# STM32H7S register map
File version: 1.4
CPU: CM7 r0p1, little endian, MPU, FPU, 4 interrupt priority bits
Registers are 32-bit, read-write, reset 0x0 unless marked. A register's access mark holds for its fields unless they carry their own. Offsets are from the block's base; [hi:lo] are bit positions; {n}, {i} and the like mark numbered series; 'fields as' and 'values as' point back to an identical list.

## PWR — Power control
Base 0x58024800
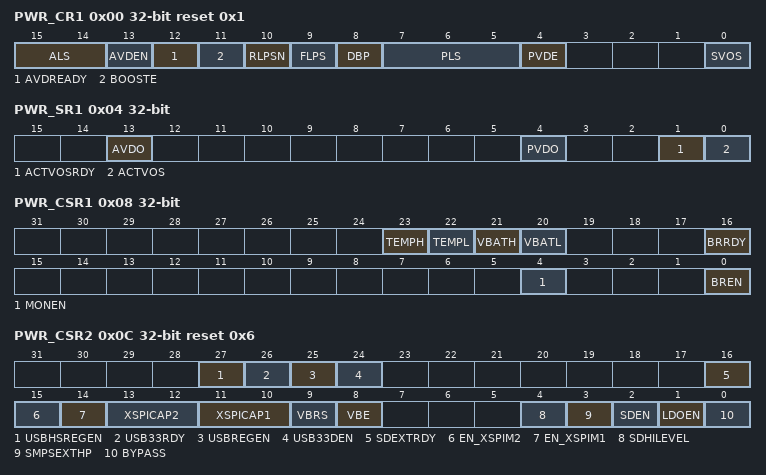
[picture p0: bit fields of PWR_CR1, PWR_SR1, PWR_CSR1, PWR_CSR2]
0x00 PWR_CR1 reset 0x1 — PWR control register 1
  [15:14] ALS — Analog voltage detector level selection These bits select the voltage threshold detected by the AVD. Note: Refer to Section Electrical characteristics of the product datasheet for more details.
    {v}=AVD level {v+1} (v=0..3)
  [13] AVDEN — Peripheral voltage monitor on VDDA enable
    0=Peripheral voltage monitor on VDDA disabled; 1=Peripheral voltage monitor on VDDA enabled
  [12] AVDREADY — analog voltage ready This bit is only used when the analog switch boost needs to be enabled (see BOOSTE bit). It must be set by software when the expected VDDA analog supply level is available. The correct analog supply level is indicated by the AVDO bit (PWR_CSR1 register) after setting the AVDEN bit and selecting the supply level to be monitored (ALS bits).
    0=peripheral analog voltage VDDA not ready (default); 1=peripheral analog voltage VDDA ready
  [11] BOOSTE — analog switch VBoost control This bit enables the booster to guarantee the analog switch AC performance when the VDD supply voltage is below 2.7 V (reduction of the total harmonic distortion to have the same switch performance over the full supply voltage range) The VDD supply voltage can be monitored through the PVD and the PLS bits.
    0=booster disabled (default); 1=booster enabled if analog voltage ready (AVD_READY = 1)
  [10] RLPSN — RAM low power mode disable in STOP. When set the RAMs will not enter to low power mode when the system enters to STOP.
    0=RAM enters to low power mode when system enters to STOP; 1=RAM remains in normal mode when system enters to STOP
  [9] FLPS — Flash low-power mode in Stop mode This bit allows to obtain the best trade-off between low-power consumption and restart time when exiting from Stop mode. When it is set, the Flash memory enters low-power mode when device is in Stop mode. consumption).
    0=Flash memory remains in normal mode when device enters Stop (quick restart time); 1=Flash memory enters low-power mode when device enters Stop mode (low-power
  [8] DBP — Disable backup domain write protection In reset state, the RCC_BDCR register, the RTC registers (including the backup registers), BREN and MOEN bits in the PWR_CSR1 register, are protected against parasitic write access. This bit must be set to enable write access to these registers.
    0=Access to RTC, RTC backup registers and backup SRAM disabled; 1=Access to RTC, RTC backup registers and backup SRAM enabled
  [7:5] PLS — Programmable voltage detector level selection These bits select the voltage threshold detected by the PVD. Note: Refer to Section Electrical characteristics of the product datasheet for more details.
    {v}=PVD level {v+1} (v=0..6); 7=External voltage level on PVD_IN pin, compared to internal VREFINT level
  [4] PVDE — Programmable voltage detector enable
    0=Programmable voltage detector disabled; 1=Programmable voltage detector enabled
  [0] SVOS — System Stop mode voltage scaling selection.
    0=SVOS Low; 1=SVOS High (default)
0x04 PWR_SR1 ro — PWR control status register 1
  [13] AVDO — Analog voltage detector output on VDDA This bit is set and cleared by hardware. It is valid only if AVD on VDDA is enabled by the AVDEN bit. Note: Since the AVD is disabled in Standby mode, this bit is equal to 0 after Standby or reset until the AVDEN bit is set
    0=VDDA is equal or higher than the AVD threshold selected with the ALS[1:0] bits; 1=VDDA is lower than the AVD threshold selected with the ALS[1:0] bits
  [4] PVDO — Programmable voltage detect output This bit is set and cleared by hardware. It is valid only if the PVD has been enabled by the PVDE bit. PLS[2:0] bits. bits. Note: Since the PVD is disabled in Standby mode, this bit is equal to 0 after Standby or reset until the PVDE bit is set.
    0=VDD or PVD_IN voltage is equal or higher than the PVD threshold selected through the; 1=VDD or PVD_IN voltage is lower than the PVD threshold selected through the PLS[2:0]
  [1] ACTVOSRDY — Voltage levels ready bit for currently used ACTVOS and SDHILEVEL This bit is set to 1 by hardware when the voltage regulator and the SMPS step-down converter are both disabled and Bypass mode is selected in PWR control register 2 (PWR_CSR2).
    0=Voltage level invalid, above or below current ACTVOS and SDHILEVEL selected levels; 1=Voltage level valid, at current ACTVOS and SDHILEVEL selected levels
  [0] ACTVOS — VOS currently applied for V<sub>CORE</sub> voltage scaling selection. These bit reflect the last VOS value applied to the PMU.
0x08 PWR_CSR1 access per field — PWR control status register 1
  [23] TEMPH ro — Temperature level monitoring versus high threshold
    0=Temperature below high threshold level; 1=Temperature equal or above high threshold level
  [22] TEMPL ro — Temperature level monitoring versus low threshold
    0=Temperature above low threshold level; 1=Temperature equal or below low threshold level
  [21] VBATH ro — V<sub>BAT</sub> level monitoring versus high threshold
    0=V<sub>BAT</sub> level below high threshold level; 1=V<sub>BAT</sub> level equal or above high threshold level
  [20] VBATL ro — V<sub>BAT</sub> level monitoring versus low threshold
    0=V<sub>BAT</sub> level above low threshold level; 1=V<sub>BAT</sub> level equal or below low threshold level
  [16] BRRDY ro — Backup regulator ready This bit is set by hardware to indicate that the backup regulator is ready.
    0=Backup regulator not ready; 1=Backup regulator ready
  [4] MONEN rw — V<sub>BAT</sub> and temperature monitoring enable When set, the V<sub>BAT</sub> supply and temperature monitoring is enabled. Note: V<sub>BAT</sub> and temperature monitoring are only available when the backup regulator is enabled (BREN bit set to 1).
    0=V<sub>BAT</sub> and temperature monitoring disabled; 1=V<sub>BAT</sub> and temperature monitoring enabled
  [0] BREN rw — Backup regulator enable When set, the backup regulator (used to maintain the backup RAM content in Standby and V<sub>BAT</sub> modes) is enabled. If BREN is reset, the backup regulator is switched off. The backup RAM can still be used in Run and Stop modes. However, its content will be lost in Standby and V<sub>BAT</sub> modes. If BREN is set, the application must wait till the backup regulator ready flag (BRRDY) is set to indicate that the data written into the SRAM will be maintained in Standby and V<sub>BAT</sub> modes.
    0=Backup regulator disabled; 1=Backup regulator enabled
0x0C PWR_CSR2 access per field reset 0x6 — PWR control register 2
  [27] USBHSREGEN rw — USB HS regulator enable.
    0=USB HS PHY regulator disabled (default); 1=USB HS PHY regulator enabled
  [26] USB33RDY ro — USB supply ready.
    0=USB33 supply not ready; 1=USB33 supply ready
  [25] USBREGEN rw — USB regulator enable.
    0=USB regulator disabled; 1=USB regulator enabled
  [24] USB33DEN rw — VDD33_USB voltage level detector enable
    0=VDD33_USB voltage level detector disabled; 1=VDD33_USB voltage level detector enabled
  [16] SDEXTRDY ro — SMPS step-down converter external supply ready This bit is set by hardware to indicate that the external supply from the SMPS step-down converter is ready.
    0=External supply not ready; 1=External supply ready
  [15] EN_XSPIM2 rw — EN_XSPIM2: this bit allows the SW to enable the XSPI interface, when available. The XSPIM_P2 supply must be stable prior to setting this bit. It should also be set when FMC is used.
  [14] EN_XSPIM1 rw — EN_XSPIM1: this bit allow the SW to enable the XSPI interface. The XSPIM_P1 supply must be stable prior to setting this bit.
  [13:12] XSPICAP2 rw — XSPI port 2 capacitor control bits see the product datasheet for more details
    0=XSPI Capacitor OFF (default) note: to confirm with analog design; 1=XSPI Capacitor set to 1/3; 2=XSPI Capacitor set to 2/3; 3=XSPI Capacitor set to full capacitance
  [11:10] XSPICAP1 rw — XSPI port 1 capacitor control bits see the product datasheet for more details
    values as XSPICAP2
  [9] VBRS rw — VBAT charging resistor selection
    0=Charge VBAT through a 5 k resistor; 1=Charge VBAT through a 1.5 k resistor
  [8] VBE rw — VBAT charging enable
    0=VBAT battery charging disabled; 1=VBAT battery charging enabled
  [4] SDHILEVEL rw-once — SMPS step-down converter voltage output for LDO or external supply This bit is used when both the LDO and SMPS step-down converter are enabled with SDEN and LDOEN enabled or when SMPSEXTHP is enabled. In this case SDHILEVEL has to be set to 1 to confirm the regulator settings
    0=Reset value; 1=1.8V
  [3] SMPSEXTHP rw-once — SMPS external power delivery selection Note: Illegal combinations of SDHILEVEL, SMPSEXTHP, SDEN, LDOEN and BYPASS are described in Table 41.
    0=SMPS normal operating mode, no power delivery to external circuits; 1=SMPS external operating mode, power delivery to external circuits
  [2] SDEN rw-once — SMPS step-down converter enable Note: Illegal combinations of SDHILEVEL, SMPSEXTHP, SDEN, LDOEN and BYPASS are described in Table 41.
    0=SMPS step-down converter disabled
  [1] LDOEN rw-once — Low drop-out regulator enable Note: Illegal combinations of SDHILEVEL, SMPSEXTHP, SDEN, LDOEN and BYPASS are described in Table 41.
    0=Low drop-out regulator disabled; 1=Low drop-out regulator enabled (default)
  [0] BYPASS rw-once — Power management unit bypass Note: Illegal combinations of SDHILEVEL, SMPSEXTHP, SDEN, LDOEN and BYPASS are described in Table 41.
    0=Power management unit normal operation; 1=Power management unit bypassed, voltage monitoring still active
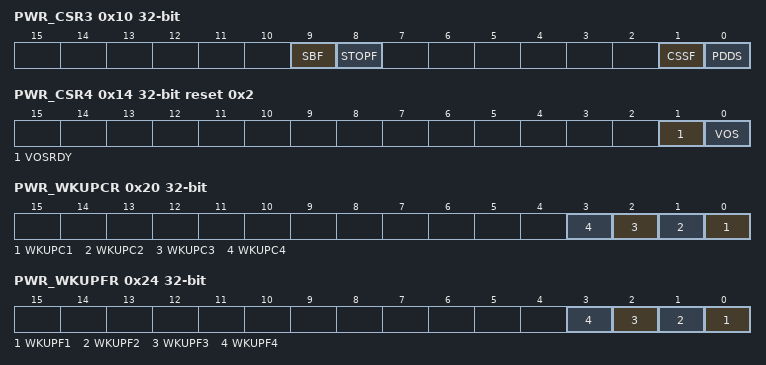
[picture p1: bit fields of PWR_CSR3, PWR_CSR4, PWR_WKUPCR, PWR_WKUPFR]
0x10 PWR_CSR3 access per field — PWR CPU control register 3
  [9] SBF ro — System Standby flag This bit is set by hardware and cleared only by a POR (Power-on Reset) or by setting the CPU CSSF bit
    0=System has not been in Standby mode; 1=System has been in Standby mode
  [8] STOPF ro — STOP flag This bit is set by hardware and cleared only by any reset or by setting the CPU CSSF bit.
    0=System has not been in Stop mode; 1=System has been in Stop mode
  [1] CSSF rw — Clear Standby and Stop flags (always read as 0) This bit is cleared to 0 by hardware.
    0=No effect; 1=flags (STOPF, SBF) are cleared
  [0] PDDS rw — Power Down Deepsleep. This bit allows CPU to define the Deepsleep mode
    0=Stop mode when device enters Deepsleep; 1=Standby mode when device enters Deepsleep
0x14 PWR_CSR4 access per field reset 0x2 — PWR control status register 4
  [1] VOSRDY ro — VOS Ready bit
    0=Not ready, voltage level below VOS selected level; 1=Ready, voltage level at or above VOS selected level
  [0] VOS rw — Voltage scaling selection according to performance These bits control the V<sub>CORE</sub> voltage level and allow to obtains the best trade-off between power consumption and performance: When increasing the performance, the voltage scaling must be changed before increasing the system frequency. When decreasing performance, the system frequency must first be decreased before changing the voltage scaling. Note: Refer to Section Electrical characteristics of the product datasheet for more details.
    0=VOS Low level (default); 1=VOS High level
0x20 PWR_WKUPCR — PWR wakeup clear register
  [n-1] WKUPC{n} (n=1..4) — Clear Wakeup pin flag for WKUP{n} These bits are always read as 0.
    0=No effect; 1=Writing 1 clears the WKUPF{n} Wakeup pin flag (bit is cleared to 0 by hardware)
0x24 PWR_WKUPFR ro — PWR wakeup flag register
  [n-1] WKUPF{n} (n=1..4) — Wakeup pin WKUP{n} flag. This bit is set by hardware and cleared only by a Reset pin or by setting the WKUPC{n} bit in the PWR wakeup clear register (PWR_WKUPCR).
    0=No wakeup event occurred; 1=A wakeup event was received from WKUP{n} pin
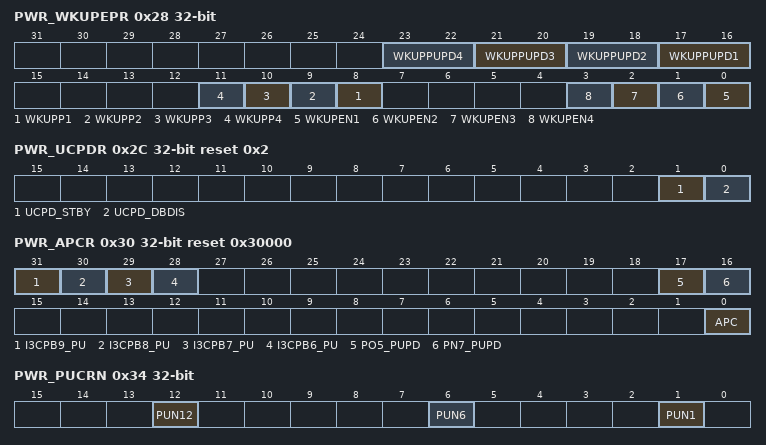
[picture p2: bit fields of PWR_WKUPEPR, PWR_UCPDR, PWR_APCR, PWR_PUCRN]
0x28 PWR_WKUPEPR — PWR wakeup enable and polarity register
  [2n+15:2n+14] WKUPPUPD{n} (n=1..4) — Wakeup pin pull configuration for WKUPn, These bits define the I/O pad pull configuration used when WKUPENn = 1. The associated GPIO port pull configuration must be set to the same value or to 00. The Wakeup pin pull configuration is kept in Standby mode.
    0=No pull-up; 1=Pull-up; 2=Pull-down; 3=FIELD Reserved
  [n+7] WKUPP{n} (n=1..4) — Wakeup pin polarity bit for WKUPn, (n = 4, 3, 2, 1) These bits define the polarity used for event detection on WKUPn external wakeup pin.
    0=Detection on high level (rising edge); 1=Detection on low level (falling edge)
  [n-1] WKUPEN{n} (n=1..4) — Enable Wakeup Pin WKUPn, (n = 4, 3, 2, 1) Each bit is set and cleared by software. Note: An additional wakeup event is detected if WKUPn+1 pin is enabled (by setting the WKUPENn bit) when WKUPn pin level is already high when WKUPPn+1 selects rising edge, or low when WKUPPn selects falling edge.
    0=An event on WKUPn pin does not wakeup the system from Standby mode; 1=A rising or falling edge on WKUPn pin wakes-up the system from Standby mode
0x2C PWR_UCPDR reset 0x2 — PWR USB Type-C and Power Delivery register
  [1] UCPD_STBY — UCPD Standby mode When set, this bit is used to memorize the UCPD configuration in Standby mode. This bit must be written to 1 just before entering Standby mode when using UCPD. It must be written to 0 after exiting the Standby mode and before writing any UCPD registers.
  [0] UCPD_DBDIS — UCPD dead battery disable
    0=UCPD dead battery pull-down behavior enabled on UCPDx_CC1 and UCPDx_CC2 pins; 1=UCPD dead battery pull-down behavior disabled on UCPDx_CC1 and UCPDx_CC2 pins
0x30 PWR_APCR reset 0x30000 — PWR apply pull configuration register
  [31] I3CPB9_PU — Port PB9 I3C pull-up bit When I3C is used on PB9, when set, this bit activates the pull-up on I3C1_SDA (PB9) in standby mode.
  [30] I3CPB8_PU — Port PB8 I3C pull-up bit When I3C is used on PB8, when set, this bit activates the pull-up on I3C1_SCL (PB8) in standby mode.
  [29] I3CPB7_PU — Port PB7 I3C pull-up bit When I3C is used on PB7, when set, this bit activates the pull-up on I3C1_SDA (PB7) in standby mode.
  [28] I3CPB6_PU — Port PB6 I3C pull-up bit When I3C is used on PB6, when set, this bit activates the pull-up on I3C1_SCL (PB6) in standby mode.
  [17] PO5_PUPD — Port O bit 5 pull-up/down configuration When this bit is set, a weak pull-up or pull down resistor is applied on PO5 following inverse logic applied on PO4. If the PUO4 bit in PWR_PUCRO register is set and APC bit is set the week pull-down is applied on PO5. If the PDO4 bit in PWR_PDCRO register is set and APC bit is set the week pull-up is applied on PO5..
  [16] PN7_PUPD — Port N bit 7 pull-up/down configuration When this bit is set, a weak pull-up or pull-down resistor is applied on PN7 following inverse logic applied on PN6. If the PUN6 bit in PWR_PUCRN register is set and APC bit is set the week pull-down is applied on PN7. If the PDN6 bit in PWR_PDCRN register is set and APC bit is set the week pull-up is applied on PN7.
  [0] APC — Apply pull-up and pull-down configuration When this bit is set, the I/O pull-up and pull-down configurations defined in PO5_PUPD, PN7_PUPD bits and PUCRx, PDCRx registers are applied in Standby mode even after wakeup until APC bit is reset to 0. When this bit is cleared, the I/O pull-up or pull-down configurations defined in PO5_PUPD, PN7_PUPD bits and PUCRx and PDCRx registers are not applied in Standby mode and IO becomes Hi-Z.
0x34 PWR_PUCRN — PWR port N pull-up control register
  [12] PUN12 — Port N pull-up bit 12 When set, each bit activates the pull-up on PN12 when the APC bit is set in PWR_APCR. The pull-up is not activated if the corresponding PD12 bit is also set.
  [6] PUN6 — Port N pull-up bit 6 When set activates the pull-up on PN6 when the APC bit is set in PWR_APCR. The pull-up is not activated if the corresponding PDN6 bit is also set.
  [1] PUN1 — Port N pull-up bit 1 When set, each bit activates the pull-up on PN1 when the APC bit is set in PWR_APCR. The pull-up is not activated if the corresponding PD1 bit is also set.
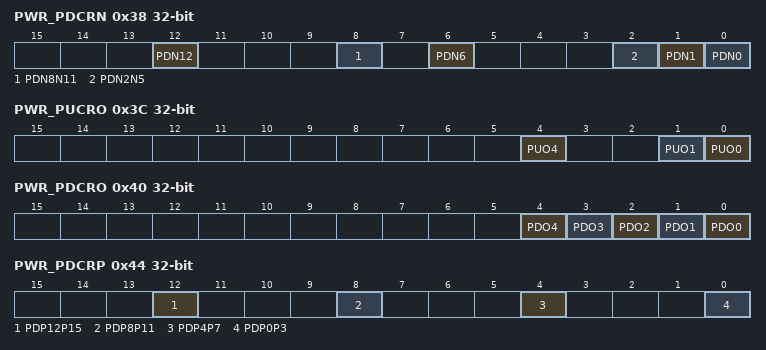
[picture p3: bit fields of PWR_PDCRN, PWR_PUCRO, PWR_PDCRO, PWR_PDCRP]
0x38 PWR_PDCRN — PWR port N pull-down control register
  [12] PDN12 — Port N pull-down bit 12 When set activates the pull-down on PN12 when the APC bit is set in PWR_APCR.
  [8] PDN8N11 — Port N - PN8 to PN11 pull-down activation When set, four pull-down resistors are activated on PN8 to PN11 when the APC bit is set in PWR_APCR.
  [6] PDN6 — Port N pull-down bit 6 When set activates the pull-down on PN6 when the APC bit is set in PWR_APCR.
  [2] PDN2N5 — Port N PN2 to PN5 pull-down activation When set, four pull-down resistors are activated on PN2 to PN5 when the APC bit is set in PWR_APCR.
  [1] PDN1 — Port N pull-down bit 1 When set activates the pull-down on PN1 when the APC bit is set in PWR_APCR.
  [0] PDN0 — Port N pull-down bit 0 When set activates the pull-down on PN0 when the APC bit is set in PWR_APCR.
0x3C PWR_PUCRO — PWR port O pull-up control register
  [4] PUO4 — Port O pull-up bit 4 When set activates the pull-up on PO4 when the APC bit is set in PWR_APCR. The pull-up is not activated if the corresponding bits PDO4 in PWR_PDCRO is also set.
  [1] PUO1 — (n = 1 to 0) Port O pull-up bits When set, each bit activates the pull-up on POy when the APC bit is set in PWR_APCR. The pull-up is not activated if the corresponding bits in PWR_PDCRO is also set.
  [0] PUO0 — (n = 1 to 0) Port O pull-up bits When set, each bit activates the pull-up on POy when the APC bit is set in PWR_APCR. The pull-up is not activated if the corresponding bits in PWR_PDCRO is also set.
0x40 PWR_PDCRO — PWR port O pull-down control register
  [n] PDO{n} (n=0..4) — Port O pull-down bit y When set, each bit activates the pull-down on POy when the APC bit is set in PWR_APCR.
0x44 PWR_PDCRP — PWR port P pull-down control register
  [12] PDP12P15 — Port P12-P15 pull-down activation When set, four pull-down resistors are activated on P8 to P11 when the APC bit is set in PWR_APCR.
  [8] PDP8P11 — Port P8-P11 pull-down activation When set, four pull-down resistors are activated on P8 to P11 when the APC bit is set in PWR_APCR.
  [4] PDP4P7 — Port P4-P7 pull-down activation When set, four pull-down resitors are activated on P4 to P7 when the APC bit is set in PWR_APCR.
  [0] PDP0P3 — Port P0-P3 pull-down activation When set, four pull-down resistors are activated on P0 to P3 when the APC bit is set in PWR_APCR.
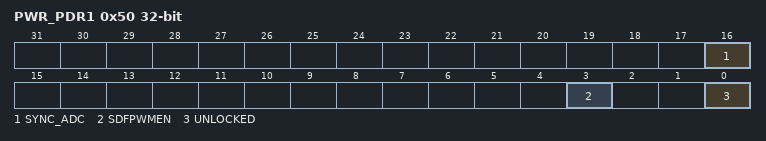
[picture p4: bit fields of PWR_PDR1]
0x50 PWR_PDR1 — PWR debug register 1
  [16] SYNC_ADC — (Non-User bit)
    0=SD_Converter clock free running; 1=SD_Converter clock synchronised to ADC
  [3] SDFPWMEN — Step down converter force PWM mode
    0=SD_Converter Normal mode; 1=SD_Converter forced PWM mode
  [0] UNLOCKED — Debug Register Unlocked.
    0=accessed locked: key was not written and after each register write access; 1=after key 0xCAFECAFE was written in this register
